# PY32F040xx register map
Vendor: Puya; Series: PY32F0; File version: 1.0.0
CPU: CM0+ r0p1, little endian, no MPU, no FPU, 4 interrupt priority bits
Registers are 32-bit, read-write, reset 0x0 unless marked. A register's access mark holds for its fields unless they carry their own. Offsets are from the block's base; [hi:lo] are bit positions; {n}, {i} and the like mark numbered series.

## IWDG — Independent watchdog
Base 0x40003000
0x00 KR wo — Key register (IWDG_KR)
  [15:0] KEY — Key value
    0x5555=Enable access to PR, RLR and WINR registers (0x5555); 0xAAAA=Reset the watchdog value (0xAAAA); 0xCCCC=Start the watchdog (0xCCCC)
0x04 PR — Prescaler register (IWDG_PR)
  [2:0] PR — Prescaler divider
    0=DivideBy4 (Divider /4); 1=DivideBy8 (Divider /8); 2=DivideBy16 (Divider /16); 3=DivideBy32 (Divider /32); 4=DivideBy64 (Divider /64); 5=DivideBy128 (Divider /128); 6=DivideBy256 (Divider /256); 7=DivideBy256bis (Divider /256)
0x08 RLR reset 0xFFF — Reload register (IWDG_RLR)
  [11:0] RL — Watchdog counter reload value
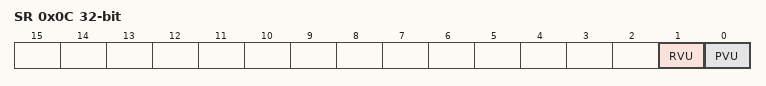
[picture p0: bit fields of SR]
0x0C SR ro — Status register (IWDG_SR)
  [1] RVU — Watchdog counter reload value update
    0=Idle (No update on-going); 1=Busy (Update on-going)
  [0] PVU — Watchdog prescaler value update
    0=Idle (No update on-going); 1=Busy (Update on-going)

## LCD — LCD CONTROLLER
Base 0x40002400
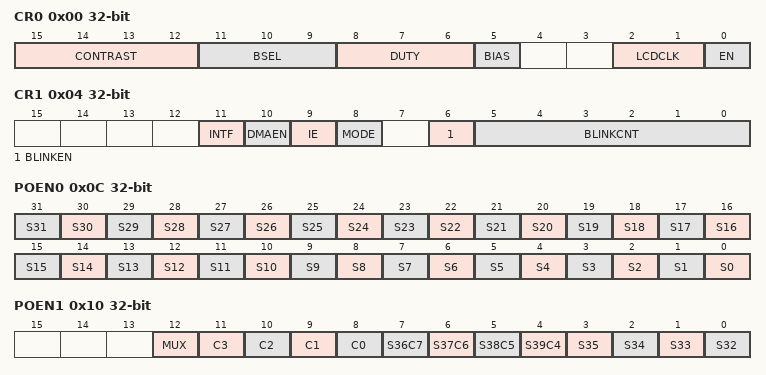
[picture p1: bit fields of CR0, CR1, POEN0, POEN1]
0x00 CR0 — Control register
  [15:12] CONTRAST
  [11:9] BSEL
    0=Ext (External resistor mode, external circuitry required); 2=IntMed (Internal resistive divider, medium power consumption mode); 4=IntSm (Internal resistive voltage divider, small power consumption mode); 6=IntHi (Internal resistive voltage divider, high power mode)
  [8:6] DUTY
    0=Static; 1=1/2 duty; 2=1/3 duty; 3=1/4 duty; 5=1/6 duty; 7=1/8 duty
  [5] BIAS
    0=1/3 bias; 1=1/2 bias
  [2:1] LCDCLK
    0=Hz64 (64 Hz); 1=Hz128 (128 Hz); 2=Hz256 (256 Hz); 3=Hz512 (512 Hz)
  [0] EN
    0=Disabled (LCD disabled); 1=Enabled (LCD enabled)
0x04 CR1
  [11] INTF
    0=NoInterrupt; 1=Interrupt
  [10] DMAEN
    0=Disabled (Disable LCD interrupt triggered DMA); 1=Enabled (Enables LCD interrupt triggering DMA)
  [9] IE
    0=Disabled (Interrupt disabled); 1=Enabled (Interrupt enabled)
  [8] MODE
  [6] BLINKEN
    0=Disabled (LCD splash screen disabled); 1=Enabled (LCD splash screen enabled)
  [5:0] BLINKCNT
0x08 INTCLR
  [10] INTF_CLR write-0-clears
    on write: 0=Clear flag
0x0C POEN0
  [n] S{n} (n=0..31)
0x10 POEN1
  [12] MUX
  [n+8] C{n} (n=0..3)
  [7] S36C7 — S36
  [6] S37C6 — S37
  [5] S38C5 — S38
  [4] S39C4 — S39
  [n-32] S{n} (n=32..35)
{0x14+4i} RAM{i} (i=0..7) — des RAM{i}
  [31:0] D — des D
{0x14+4i} RAM{i} (i=8..15) — des RAM{i}
  [7:0] D — des D

## LPTIM1 — Low power timer
Base 0x40007C00
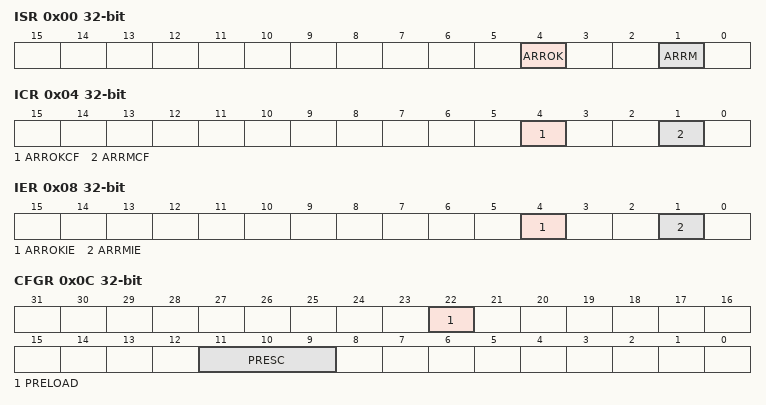
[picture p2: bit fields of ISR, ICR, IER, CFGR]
0x00 ISR ro — Interrupt and Status Register
  [4] ARROK — Autoreload match update OK
  [1] ARRM — Autoreload match
    1=Set (Autoreload match)
0x04 ICR wo — Interrupt Clear Register
  [4] ARROKCF — Autoreload match update OK Clear Flag
  [1] ARRMCF — Autoreload match Clear Flag
    1=Clear (Autoreload match Clear Flag)
0x08 IER — Interrupt Enable Register
  [4] ARROKIE — Autoreload match update OK Interrupt Enable
  [1] ARRMIE — Autoreload matchInterrupt Enable
    0=Disabled (ARRM interrupt disabled); 1=Enabled (ARRM interrupt enabled)
0x0C CFGR — Configuration Register
  [22] PRELOAD — Registers update mode
    0=Immediate (Registers are updated after each APB bus write access); 1=EndOfPeriod (Registers are updated at the end of the current LPTIM period)
  [11:9] PRESC — Clock prescaler
    0=Div1 (/1); 1=Div2 (/2); 2=Div4 (/4); 3=Div8 (/8); 4=Div16 (/16); 5=Div32 (/32); 6=Div64 (/64); 7=Div128 (/128)
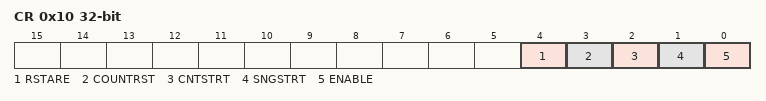
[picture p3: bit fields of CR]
0x10 CR — Control Register
  [4] RSTARE — Reset after read enable
    0=Disabled (CNT Register reads do not trigger reset); 1=Enabled (CNT Register reads trigger reset of LPTIM)
  [3] COUNTRST — LPTIM counter reset
  [2] CNTSTRT
  [1] SNGSTRT — LPTIM start in single mode
    on write: 1=Start (LPTIM start in Single mode)
  [0] ENABLE — LPTIM Enable
    0=Disabled (LPTIM is disabled); 1=Enabled (LPTIM is enabled)
0x18 ARR reset 0x1 — Autoreload Register
  [15:0] ARR — Auto reload value
0x1C CNT ro — Counter Register
  [15:0] CNT — Counter value
